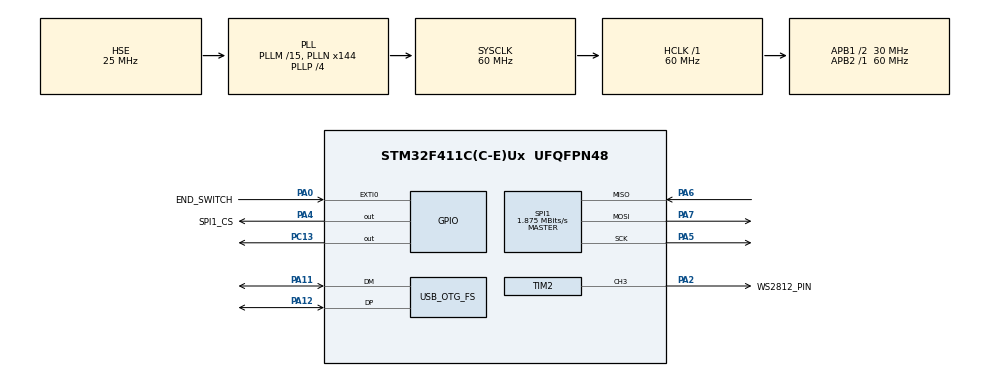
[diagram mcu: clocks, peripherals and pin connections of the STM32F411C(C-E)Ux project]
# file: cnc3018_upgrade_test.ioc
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Dma.Request0=TIM2_CH3/UP
Dma.TIM2_CH3/UP.0.Direction=DMA_MEMORY_TO_PERIPH
Dma.TIM2_CH3/UP.0.FIFOMode=DMA_FIFOMODE_DISABLE
Dma.TIM2_CH3/UP.0.Instance=DMA1_Stream1
Dma.TIM2_CH3/UP.0.MemDataAlignment=DMA_MDATAALIGN_WORD
Dma.TIM2_CH3/UP.0.MemInc=DMA_MINC_ENABLE
Dma.TIM2_CH3/UP.0.Mode=DMA_CIRCULAR
Dma.TIM2_CH3/UP.0.PeriphDataAlignment=DMA_PDATAALIGN_WORD
Dma.TIM2_CH3/UP.0.PeriphInc=DMA_PINC_DISABLE
Dma.TIM2_CH3/UP.0.Priority=DMA_PRIORITY_HIGH
FATFS._FS_LOCK=3
FATFS._MAX_SS=4096
FATFS._MIN_SS=4096
FATFS._USE_MUTEX=1
FREERTOS.INCLUDE_uxTaskGetStackHighWaterMark2=1
FREERTOS.Tasks01=defaultTask,24,8192,StartDefaultTask,Default,NULL,Dynamic,NULL,NULL
FREERTOS.configCHECK_FOR_STACK_OVERFLOW=2
FREERTOS.configENABLE_FPU=1
FREERTOS.configGENERATE_RUN_TIME_STATS=1
FREERTOS.configMINIMAL_STACK_SIZE=1024
FREERTOS.configRECORD_STACK_HIGH_ADDRESS=1
FREERTOS.configTOTAL_HEAP_SIZE=80000
FREERTOS.configUSE_MALLOC_FAILED_HOOK=1
FREERTOS.configUSE_NEWLIB_REENTRANT=1
FREERTOS.configUSE_POSIX_ERRNO=1
Mcu.Family=STM32F4
Mcu.Name=STM32F411C(C-E)Ux
Mcu.Package=UFQFPN48
NVIC.DMA1_Stream1_IRQn=true\:5\:0\:false\:false\:true\:true\:false\:true\:true
NVIC.EXTI0_IRQn=true\:5\:0\:false\:false\:true\:true\:true\:true\:true
NVIC.OTG_FS_IRQn=true\:6\:0\:true\:false\:true\:true\:true\:true\:true
NVIC.PVD_IRQn=true\:5\:0\:false\:false\:true\:true\:true\:true\:true
NVIC.PriorityGroup=NVIC_PRIORITYGROUP_4
NVIC.TIM3_IRQn=true\:15\:0\:false\:false\:true\:false\:false\:true\:true
NVIC.TimeBase=TIM3_IRQn
NVIC.TimeBaseIP=TIM3
NimaLTD.I-CUBE-SPIF.2.3.0.DriverJjSPIF=true
NimaLTD.I-CUBE-SPIF.2.3.0.SPIF_DEBUG=SPIF_DEBUG_DISABLE
NimaLTD.I-CUBE-SPIF.2.3.0.SPIF_RTOS=SPIF_RTOS_CMSIS_V2
PA0-WKUP.GPIO_Label=END_SWITCH
PA0-WKUP.GPIO_ModeDefaultEXTI=GPIO_MODE_IT_FALLING
PA0-WKUP.Signal=GPXTI0
PA11.Mode=Device_Only
PA11.Signal=USB_OTG_FS_DM
PA12.Mode=Device_Only
PA12.Signal=USB_OTG_FS_DP
PA13.Mode=Serial_Wire
PA13.Signal=SYS_JTMS-SWDIO
PA14.Mode=Serial_Wire
PA14.Signal=SYS_JTCK-SWCLK
PA2.GPIO_Label=WS2812_PIN
PA2.Signal=S_TIM2_CH3
PA4.GPIO_Label=SPI1_CS
PA4.GPIO_Speed=GPIO_SPEED_FREQ_VERY_HIGH
PA4.Signal=GPIO_Output
PA5.Mode=Full_Duplex_Master
PA5.Signal=SPI1_SCK
PA6.Mode=Full_Duplex_Master
PA6.Signal=SPI1_MISO
PA7.Mode=Full_Duplex_Master
PA7.Signal=SPI1_MOSI
PC13-ANTI_TAMP.Signal=GPIO_Output
PC14-OSC32_IN.Mode=LSE-External-Oscillator
PC14-OSC32_IN.Signal=RCC_OSC32_IN
PC15-OSC32_OUT.Mode=LSE-External-Oscillator
PC15-OSC32_OUT.Signal=RCC_OSC32_OUT
PH0\ -\ OSC_IN.Mode=HSE-External-Oscillator
PH0\ -\ OSC_IN.Signal=RCC_OSC_IN
PH1\ -\ OSC_OUT.Mode=HSE-External-Oscillator
PH1\ -\ OSC_OUT.Signal=RCC_OSC_OUT
ProjectManager.HeapSize=0x100
ProjectManager.StackSize=0x100
ProjectManager.TargetToolchain=STM32CubeIDE
RCC.48MHZClocksFreq_Value=48000000
RCC.AHBFreq_Value=60000000
RCC.APB1CLKDivider=RCC_HCLK_DIV2
RCC.APB1Freq_Value=30000000
RCC.APB1TimFreq_Value=60000000
RCC.APB2Freq_Value=60000000
RCC.APB2TimFreq_Value=60000000
RCC.CortexFreq_Value=60000000
RCC.EnbaleCSS=true
RCC.HCLKFreq_Value=60000000
RCC.HSE_VALUE=25000000
RCC.HSI_VALUE=16000000
RCC.PLLM=15
RCC.PLLN=144
RCC.PLLP=RCC_PLLP_DIV4
RCC.PLLQ=5
RCC.PWR_Regulator_Voltage_Scale=PWR_REGULATOR_VOLTAGE_SCALE1
RCC.SYSCLKFreq_VALUE=60000000
RCC.SYSCLKSource=RCC_SYSCLKSOURCE_PLLCLK
RCC.VCOOutputFreq_Value=240000000
SH.S_TIM2_CH3.0=TIM2_CH3,PWM Generation3 CH3
SPI1.BaudRatePrescaler=SPI_BAUDRATEPRESCALER_32
SPI1.CLKPhase=SPI_PHASE_1EDGE
SPI1.CLKPolarity=SPI_POLARITY_LOW
SPI1.CalculateBaudRate=1.875 MBits/s
SPI1.Direction=SPI_DIRECTION_2LINES
SPI1.Mode=SPI_MODE_MASTER
SPI1.VirtualType=VM_MASTER
TIM2.AutoReloadPreload=TIM_AUTORELOAD_PRELOAD_ENABLE
TIM2.Channel-PWM\ Generation3\ CH3=TIM_CHANNEL_3
TIM2.OC3Preload_PWM=ENABLE
TIM2.OCFastMode_PWM-PWM\ Generation3\ CH3=TIM_OCFAST_ENABLE
TIM2.OCMode_PWM-PWM\ Generation3\ CH3=TIM_OCMODE_PWM1
TIM2.Period=75
TIM2.Pulse-PWM\ Generation3\ CH3=75
TIM2.TIM_MasterOutputTrigger=TIM_TRGO_RESET
TIM2.TIM_MasterSlaveMode=TIM_MASTERSLAVEMODE_DISABLE
USB_OTG_FS.VirtualMode=Device_Only
VP_FATFS_VS_Generic.Mode=User_defined
VP_FREERTOS_VS_CMSIS_V2.Mode=CMSIS_V2
VP_NimaLTD.I-CUBE-SPIF_VS_DriverJjSPIF_1.0.0_2.3.0.Mode=DriverJjSPIF
VP_SYS_VS_tim3.Mode=TIM3
VP_TIM2_VS_ClockSourceINT.Mode=Internal
board=custom

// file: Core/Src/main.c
/* USER CODE BEGIN Header */
/**
 ******************************************************************************
 * @file           : main.c
 * @brief          : Main program body
 ******************************************************************************
 * @attention
 *
 * Copyright (c) 2024 STMicroelectronics.
 * All rights reserved.
 *
 * This software is licensed under terms that can be found in the LICENSE file
 * in the root directory of this software component.
 * If no LICENSE file comes with this software, it is provided AS-IS.
 *
 ******************************************************************************
 */
/* USER CODE END Header */
#include "main.h"
#include "cmsis_os.h"
#include "fatfs.h"

/* USER CODE BEGIN Includes */
#include <spif.h>
#include "cbor.h"
#include "SEGGER_RTT.h"
#include "SEGGER_SYSVIEW.h"
#include "Application.h"
/* USER CODE END Includes */

SPI_HandleTypeDef hspi1;

TIM_HandleTypeDef htim2;
DMA_HandleTypeDef hdma_tim2_ch3_up;

PCD_HandleTypeDef hpcd_USB_OTG_FS;

/* Definitions for defaultTask */
osThreadId_t defaultTaskHandle;
const osThreadAttr_t defaultTask_attributes = {
  .name = "defaultTask",
  .stack_size = 8192 * 4,
  .priority = (osPriority_t) osPriorityNormal,
};
/* USER CODE BEGIN PV */
SPIF_HandleTypeDef g_peripheral;
/* USER CODE END PV */

void SystemClock_Config(void);
static void MX_GPIO_Init(void);
static void MX_DMA_Init(void);
static void MX_TIM2_Init(void);
static void MX_SPI1_Init(void);
static void MX_USB_OTG_FS_PCD_Init(void);
void StartDefaultTask(void *argument);

int main(void)
{

  /* MCU Configuration--------------------------------------------------------*/

  /* Reset of all peripherals, Initializes the Flash interface and the Systick. */
  HAL_Init();

  /* Configure the system clock */
  SystemClock_Config();

  /* Initialize all configured peripherals */
  MX_GPIO_Init();
  MX_DMA_Init();
  MX_TIM2_Init();
  MX_SPI1_Init();
  MX_FATFS_Init();
  MX_USB_OTG_FS_PCD_Init();
  /* USER CODE BEGIN 2 */
  SEGGER_RTT_Init();
  SEGGER_SYSVIEW_Conf();

  /* USER CODE END 2 */

  /* Init scheduler */
  osKernelInitialize();

  /* Create the thread(s) */
  /* creation of defaultTask */
  defaultTaskHandle = osThreadNew(StartDefaultTask, NULL, &defaultTask_attributes);

  /* Start scheduler */
  osKernelStart();

  /* We should never get here as control is now taken by the scheduler */
  /* Infinite loop */
	while (1) {

	}
}

void SystemClock_Config(void)
{
  RCC_OscInitTypeDef RCC_OscInitStruct = {0};
  RCC_ClkInitTypeDef RCC_ClkInitStruct = {0};

  /** Configure the main internal regulator output voltage
  */
  __HAL_RCC_PWR_CLK_ENABLE();
  __HAL_PWR_VOLTAGESCALING_CONFIG(PWR_REGULATOR_VOLTAGE_SCALE1);

  /** Initializes the RCC Oscillators according to the specified parameters
  * in the RCC_OscInitTypeDef structure.
  */
  RCC_OscInitStruct.OscillatorType = RCC_OSCILLATORTYPE_HSE;
  RCC_OscInitStruct.HSEState = RCC_HSE_ON;
  RCC_OscInitStruct.PLL.PLLState = RCC_PLL_ON;
  RCC_OscInitStruct.PLL.PLLSource = RCC_PLLSOURCE_HSE;
  RCC_OscInitStruct.PLL.PLLM = 15;
  RCC_OscInitStruct.PLL.PLLN = 144;
  RCC_OscInitStruct.PLL.PLLP = RCC_PLLP_DIV4;
  RCC_OscInitStruct.PLL.PLLQ = 5;
  if (HAL_RCC_OscConfig(&RCC_OscInitStruct) != HAL_OK)
  {
    Error_Handler();
  }

  /** Initializes the CPU, AHB and APB buses clocks
  */
  RCC_ClkInitStruct.ClockType = RCC_CLOCKTYPE_HCLK|RCC_CLOCKTYPE_SYSCLK
                              |RCC_CLOCKTYPE_PCLK1|RCC_CLOCKTYPE_PCLK2;
  RCC_ClkInitStruct.SYSCLKSource = RCC_SYSCLKSOURCE_PLLCLK;
  RCC_ClkInitStruct.AHBCLKDivider = RCC_SYSCLK_DIV1;
  RCC_ClkInitStruct.APB1CLKDivider = RCC_HCLK_DIV2;
  RCC_ClkInitStruct.APB2CLKDivider = RCC_HCLK_DIV1;

  if (HAL_RCC_ClockConfig(&RCC_ClkInitStruct, FLASH_LATENCY_1) != HAL_OK)
  {
    Error_Handler();
  }

  /** Enables the Clock Security System
  */
  HAL_RCC_EnableCSS();
}

static void MX_SPI1_Init(void)
{

  /* SPI1 parameter configuration*/
  hspi1.Instance = SPI1;
  hspi1.Init.Mode = SPI_MODE_MASTER;
  hspi1.Init.Direction = SPI_DIRECTION_2LINES;
  hspi1.Init.DataSize = SPI_DATASIZE_8BIT;
  hspi1.Init.CLKPolarity = SPI_POLARITY_LOW;
  hspi1.Init.CLKPhase = SPI_PHASE_1EDGE;
  hspi1.Init.NSS = SPI_NSS_SOFT;
  hspi1.Init.BaudRatePrescaler = SPI_BAUDRATEPRESCALER_32;
  hspi1.Init.FirstBit = SPI_FIRSTBIT_MSB;
  hspi1.Init.TIMode = SPI_TIMODE_DISABLE;
  hspi1.Init.CRCCalculation = SPI_CRCCALCULATION_DISABLE;
  hspi1.Init.CRCPolynomial = 10;
  if (HAL_SPI_Init(&hspi1) != HAL_OK)
  {
    Error_Handler();
  }

}

static void MX_TIM2_Init(void)
{

  TIM_ClockConfigTypeDef sClockSourceConfig = {0};
  TIM_MasterConfigTypeDef sMasterConfig = {0};
  TIM_OC_InitTypeDef sConfigOC = {0};

  htim2.Instance = TIM2;
  htim2.Init.Prescaler = 0;
  htim2.Init.CounterMode = TIM_COUNTERMODE_UP;
  htim2.Init.Period = 75;
  htim2.Init.ClockDivision = TIM_CLOCKDIVISION_DIV1;
  htim2.Init.AutoReloadPreload = TIM_AUTORELOAD_PRELOAD_ENABLE;
  if (HAL_TIM_Base_Init(&htim2) != HAL_OK)
  {
    Error_Handler();
  }
  sClockSourceConfig.ClockSource = TIM_CLOCKSOURCE_INTERNAL;
  if (HAL_TIM_ConfigClockSource(&htim2, &sClockSourceConfig) != HAL_OK)
  {
    Error_Handler();
  }
  if (HAL_TIM_PWM_Init(&htim2) != HAL_OK)
  {
    Error_Handler();
  }
  sMasterConfig.MasterOutputTrigger = TIM_TRGO_RESET;
  sMasterConfig.MasterSlaveMode = TIM_MASTERSLAVEMODE_DISABLE;
  if (HAL_TIMEx_MasterConfigSynchronization(&htim2, &sMasterConfig) != HAL_OK)
  {
    Error_Handler();
  }
  sConfigOC.OCMode = TIM_OCMODE_PWM1;
  sConfigOC.Pulse = 75;
  sConfigOC.OCPolarity = TIM_OCPOLARITY_HIGH;
  sConfigOC.OCFastMode = TIM_OCFAST_ENABLE;
  if (HAL_TIM_PWM_ConfigChannel(&htim2, &sConfigOC, TIM_CHANNEL_3) != HAL_OK)
  {
    Error_Handler();
  }
  HAL_TIM_MspPostInit(&htim2);

}

static void MX_USB_OTG_FS_PCD_Init(void)
{

  hpcd_USB_OTG_FS.Instance = USB_OTG_FS;
  hpcd_USB_OTG_FS.Init.dev_endpoints = 4;
  hpcd_USB_OTG_FS.Init.speed = PCD_SPEED_FULL;
  hpcd_USB_OTG_FS.Init.dma_enable = DISABLE;
  hpcd_USB_OTG_FS.Init.phy_itface = PCD_PHY_EMBEDDED;
  hpcd_USB_OTG_FS.Init.Sof_enable = DISABLE;
  hpcd_USB_OTG_FS.Init.low_power_enable = DISABLE;
  hpcd_USB_OTG_FS.Init.lpm_enable = DISABLE;
  hpcd_USB_OTG_FS.Init.vbus_sensing_enable = DISABLE;
  hpcd_USB_OTG_FS.Init.use_dedicated_ep1 = DISABLE;
  if (HAL_PCD_Init(&hpcd_USB_OTG_FS) != HAL_OK)
  {
    Error_Handler();
  }

}

static void MX_DMA_Init(void)
{

  /* DMA controller clock enable */
  __HAL_RCC_DMA1_CLK_ENABLE();

  /* DMA interrupt init */
  /* DMA1_Stream1_IRQn interrupt configuration */
  HAL_NVIC_SetPriority(DMA1_Stream1_IRQn, 5, 0);
  HAL_NVIC_EnableIRQ(DMA1_Stream1_IRQn);

}

static void MX_GPIO_Init(void)
{
  GPIO_InitTypeDef GPIO_InitStruct = {0};

  /* GPIO Ports Clock Enable */
  __HAL_RCC_GPIOC_CLK_ENABLE();
  __HAL_RCC_GPIOH_CLK_ENABLE();
  __HAL_RCC_GPIOA_CLK_ENABLE();

  /*Configure GPIO pin Output Level */
  HAL_GPIO_WritePin(GPIOC, GPIO_PIN_13, GPIO_PIN_RESET);

  /*Configure GPIO pin Output Level */
  HAL_GPIO_WritePin(SPI1_CS_GPIO_Port, SPI1_CS_Pin, GPIO_PIN_RESET);

  /*Configure GPIO pin : PC13 */
  GPIO_InitStruct.Pin = GPIO_PIN_13;
  GPIO_InitStruct.Mode = GPIO_MODE_OUTPUT_PP;
  GPIO_InitStruct.Pull = GPIO_NOPULL;
  GPIO_InitStruct.Speed = GPIO_SPEED_FREQ_LOW;
  HAL_GPIO_Init(GPIOC, &GPIO_InitStruct);

  /*Configure GPIO pin : END_SWITCH_Pin */
  GPIO_InitStruct.Pin = END_SWITCH_Pin;
  GPIO_InitStruct.Mode = GPIO_MODE_IT_FALLING;
  GPIO_InitStruct.Pull = GPIO_NOPULL;
  HAL_GPIO_Init(END_SWITCH_GPIO_Port, &GPIO_InitStruct);

  /*Configure GPIO pin : SPI1_CS_Pin */
  GPIO_InitStruct.Pin = SPI1_CS_Pin;
  GPIO_InitStruct.Mode = GPIO_MODE_OUTPUT_PP;
  GPIO_InitStruct.Pull = GPIO_NOPULL;
  GPIO_InitStruct.Speed = GPIO_SPEED_FREQ_VERY_HIGH;
  HAL_GPIO_Init(SPI1_CS_GPIO_Port, &GPIO_InitStruct);

  /* EXTI interrupt init*/
  HAL_NVIC_SetPriority(EXTI0_IRQn, 5, 0);
  HAL_NVIC_EnableIRQ(EXTI0_IRQn);

}

/* USER CODE BEGIN 4 */
//extern __IO uint32_t uwTick;
//
//uint32_t HAL_GetTick(void){
//	osKernelState_t kernelState =  osKernelGetState();
//	if(kernelState == osKernelRunning){
//		return osKernelGetSysTimerCount();
//	}
//	return uwTick;
//
//}
/* USER CODE END 4 */

void StartDefaultTask(void *argument)
{
  /* USER CODE BEGIN 5 */
	StartApplication();

	/* Infinite loop */
	for (;;) {
		osDelay(1);
	}
  /* USER CODE END 5 */
}

void HAL_TIM_PeriodElapsedCallback(TIM_HandleTypeDef *htim)
{
  if (htim->Instance == TIM3) {
    HAL_IncTick();
  }
}

void Error_Handler(void)
{
  /* USER CODE BEGIN Error_Handler_Debug */
	/* User can add his own implementation to report the HAL error return state */
	__disable_irq();
	fprintf(stderr, "In Error handler");
	while (1) {
	}
  /* USER CODE END Error_Handler_Debug */
}

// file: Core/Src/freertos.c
/* USER CODE BEGIN Header */
/**
  ******************************************************************************
  * File Name          : freertos.c
  * Description        : Code for freertos applications
  ******************************************************************************
  * @attention
  *
  * Copyright (c) 2024 STMicroelectronics.
  * All rights reserved.
  *
  * This software is licensed under terms that can be found in the LICENSE file
  * in the root directory of this software component.
  * If no LICENSE file comes with this software, it is provided AS-IS.
  *
  ******************************************************************************
  */
/* USER CODE END Header */

#include "FreeRTOS.h"
#include "task.h"
#include "main.h"

/* USER CODE BEGIN Includes */
#include "assert.h"
/* USER CODE END Includes */

/* Hook prototypes */
void configureTimerForRunTimeStats(void);
unsigned long getRunTimeCounterValue(void);
void vApplicationStackOverflowHook(xTaskHandle xTask, signed char *pcTaskName);
void vApplicationMallocFailedHook(void);

/* USER CODE BEGIN 1 */
/* Functions needed when configGENERATE_RUN_TIME_STATS is on */
__weak void configureTimerForRunTimeStats(void)
{

}

__weak unsigned long getRunTimeCounterValue(void)
{
return 0;
}
/* USER CODE END 1 */

/* USER CODE BEGIN 4 */
void vApplicationStackOverflowHook(xTaskHandle xTask, signed char *pcTaskName)
{
	assert(0);
   /* Run time stack overflow checking is performed if
   configCHECK_FOR_STACK_OVERFLOW is defined to 1 or 2. This hook function is
   called if a stack overflow is detected. */
}
/* USER CODE END 4 */

/* USER CODE BEGIN 5 */
void vApplicationMallocFailedHook(void)
{
	assert(0);
   /* vApplicationMallocFailedHook() will only be called if
   configUSE_MALLOC_FAILED_HOOK is set to 1 in FreeRTOSConfig.h. It is a hook
   function that will get called if a call to pvPortMalloc() fails.
   pvPortMalloc() is called internally by the kernel whenever a task, queue,
   timer or semaphore is created. It is also called by various parts of the
   demo application. If heap_1.c or heap_2.c are used, then the size of the
   heap available to pvPortMalloc() is defined by configTOTAL_HEAP_SIZE in
   FreeRTOSConfig.h, and the xPortGetFreeHeapSize() API function can be used
   to query the size of free heap space that remains (although it does not
   provide information on how the remaining heap might be fragmented). */
}
/* USER CODE END 5 */
